# ESP32-H21 register map
Vendor: ESPRESSIF SYSTEMS (SHANGHAI) CO., LTD.; Series: ESP32 H-Series; File version: 1
CPU: RV32IMAC r0p0, little endian, no MPU, no FPU, 0 interrupt priority bits
Address unit: 32 bits
Registers are 32-bit, read-write, reset 0x0 unless marked. A register's access mark holds for its fields unless they carry their own. Offsets are from the block's base; [hi:lo] are bit positions; <NAME> marks a mode.

## PCR — PCR Peripheral
Base 0x60096000
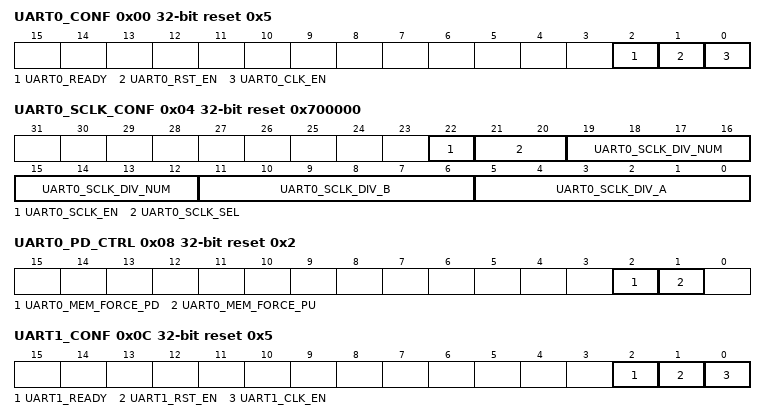
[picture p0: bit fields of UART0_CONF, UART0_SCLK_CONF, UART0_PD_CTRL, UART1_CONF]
0x00 UART0_CONF access per field reset 0x5 — UART0 configuration register
  [2] UART0_READY ro — Query this field after reset uart0 module
  [1] UART0_RST_EN rw — Set 0 to reset uart0 module
  [0] UART0_CLK_EN rw — Set 1 to enable uart0 apb clock
0x04 UART0_SCLK_CONF reset 0x700000 — UART0_SCLK configuration register
  [22] UART0_SCLK_EN — Set 1 to enable uart0 function clock
  [21:20] UART0_SCLK_SEL — set this field to select clock-source. 0: do not select anyone clock, 1: 80MHz, 2: FOSC, 3(default): XTAL.
  [19:12] UART0_SCLK_DIV_NUM — The integral part of the frequency divider factor of the uart0 function clock.
  [11:6] UART0_SCLK_DIV_B — The numerator of the frequency divider factor of the uart0 function clock.
  [5:0] UART0_SCLK_DIV_A — The denominator of the frequency divider factor of the uart0 function clock.
0x08 UART0_PD_CTRL reset 0x2 — UART0 power control register
  [2] UART0_MEM_FORCE_PD — Set this bit to force power up UART0 memory.
  [1] UART0_MEM_FORCE_PU — Set this bit to force power down UART0 memory.
0x0C UART1_CONF access per field reset 0x5 — UART1 configuration register
  [2] UART1_READY ro — Query this field after reset uart1 module
  [1] UART1_RST_EN rw — Set 0 to reset uart1 module
  [0] UART1_CLK_EN rw — Set 1 to enable uart1 apb clock
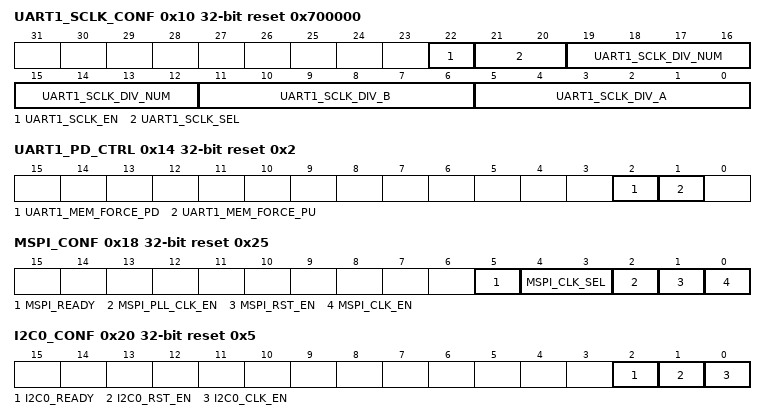
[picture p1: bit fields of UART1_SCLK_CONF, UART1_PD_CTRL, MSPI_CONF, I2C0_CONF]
0x10 UART1_SCLK_CONF reset 0x700000 — UART1_SCLK configuration register
  [22] UART1_SCLK_EN — Set 1 to enable uart0 function clock
  [21:20] UART1_SCLK_SEL — set this field to select clock-source. 0: do not select anyone clock, 1: 80MHz, 2: FOSC, 3(default): XTAL.
  [19:12] UART1_SCLK_DIV_NUM — The integral part of the frequency divider factor of the uart1 function clock.
  [11:6] UART1_SCLK_DIV_B — The numerator of the frequency divider factor of the uart1 function clock.
  [5:0] UART1_SCLK_DIV_A — The denominator of the frequency divider factor of the uart1 function clock.
0x14 UART1_PD_CTRL reset 0x2 — UART1 power control register
  [2] UART1_MEM_FORCE_PD — Set this bit to force power up UART1 memory.
  [1] UART1_MEM_FORCE_PU — Set this bit to force power down UART1 memory.
0x18 MSPI_CONF access per field reset 0x25 — MSPI configuration register
  [5] MSPI_READY ro — Query this field after reset mspi module
  [4:3] MSPI_CLK_SEL rw — set this field to select clock-source.
  [2] MSPI_PLL_CLK_EN rw — Set 1 to enable mspi pll clock
  [1] MSPI_RST_EN rw — Set 0 to reset mspi module
  [0] MSPI_CLK_EN rw — Set 1 to enable mspi clock, include mspi pll clock
0x1C MSPI_CLK_CONF — MSPI_CLK configuration register
  [7:0] MSPI_FAST_DIV_NUM — Set as one within (0,1,2) to generate div1(default)/div2/div4 of low-speed clock-source to drive clk_mspi_fast. Only avaiable whe the clck-source is a low-speed clock-source such as XTAL/FOSC.
0x20 I2C0_CONF access per field reset 0x5 — I2C configuration register
  [2] I2C0_READY ro — Query this field after reset i2c0 module
  [1] I2C0_RST_EN rw — Set 0 to reset i2c module
  [0] I2C0_CLK_EN rw — Set 1 to enable i2c apb clock
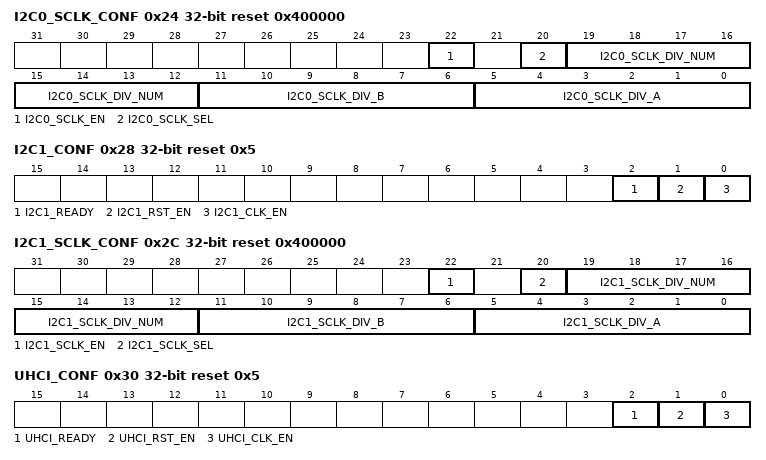
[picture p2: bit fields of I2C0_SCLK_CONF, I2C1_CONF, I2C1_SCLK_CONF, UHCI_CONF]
0x24 I2C0_SCLK_CONF reset 0x400000 — I2C_SCLK configuration register
  [22] I2C0_SCLK_EN — Set 1 to enable i2c function clock
  [20] I2C0_SCLK_SEL — set this field to select clock-source. 0(default): XTAL, 1: FOSC.
  [19:12] I2C0_SCLK_DIV_NUM — The integral part of the frequency divider factor of the i2c function clock.
  [11:6] I2C0_SCLK_DIV_B — The numerator of the frequency divider factor of the i2c function clock.
  [5:0] I2C0_SCLK_DIV_A — The denominator of the frequency divider factor of the i2c function clock.
0x28 I2C1_CONF access per field reset 0x5 — I2C configuration register
  [2] I2C1_READY ro — Query this field after reset i2c1 module
  [1] I2C1_RST_EN rw — Set 0 to reset i2c module
  [0] I2C1_CLK_EN rw — Set 1 to enable i2c apb clock
0x2C I2C1_SCLK_CONF reset 0x400000 — I2C_SCLK configuration register
  [22] I2C1_SCLK_EN — Set 1 to enable i2c function clock
  [20] I2C1_SCLK_SEL — set this field to select clock-source. 0(default): XTAL, 1: FOSC.
  [19:12] I2C1_SCLK_DIV_NUM — The integral part of the frequency divider factor of the i2c function clock.
  [11:6] I2C1_SCLK_DIV_B — The numerator of the frequency divider factor of the i2c function clock.
  [5:0] I2C1_SCLK_DIV_A — The denominator of the frequency divider factor of the i2c function clock.
0x30 UHCI_CONF access per field reset 0x5 — UHCI configuration register
  [2] UHCI_READY ro — Query this field after reset uhci module
  [1] UHCI_RST_EN rw — Set 0 to reset uhci module
  [0] UHCI_CLK_EN rw — Set 1 to enable uhci clock
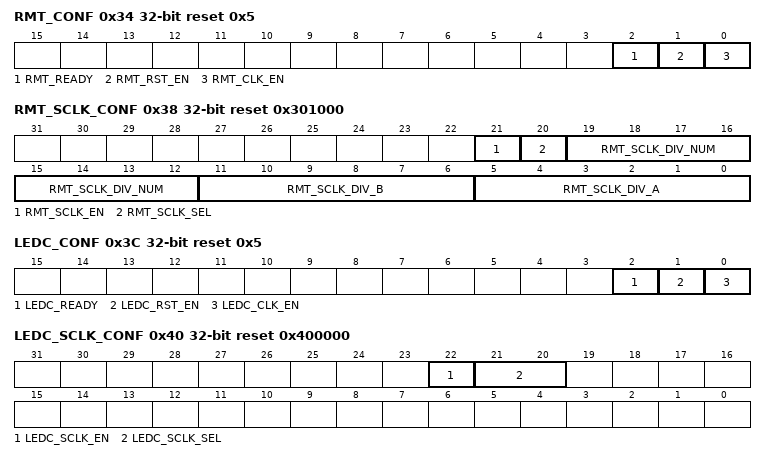
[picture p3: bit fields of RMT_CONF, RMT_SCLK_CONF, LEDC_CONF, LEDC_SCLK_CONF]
0x34 RMT_CONF access per field reset 0x5 — RMT configuration register
  [2] RMT_READY ro — Query this field after reset rmt module
  [1] RMT_RST_EN rw — Set 0 to reset rmt module
  [0] RMT_CLK_EN rw — Set 1 to enable rmt apb clock
0x38 RMT_SCLK_CONF reset 0x301000 — RMT_SCLK configuration register
  [21] RMT_SCLK_EN — Set 1 to enable rmt function clock
  [20] RMT_SCLK_SEL — set this field to select clock-source. 0: do not select anyone clock, 1(default): 80MHz, 2: FOSC, 3: XTAL.
  [19:12] RMT_SCLK_DIV_NUM — The integral part of the frequency divider factor of the rmt function clock.
  [11:6] RMT_SCLK_DIV_B — The numerator of the frequency divider factor of the rmt function clock.
  [5:0] RMT_SCLK_DIV_A — The denominator of the frequency divider factor of the rmt function clock.
0x3C LEDC_CONF access per field reset 0x5 — LEDC configuration register
  [2] LEDC_READY ro — Query this field after reset ledc module
  [1] LEDC_RST_EN rw — Set 0 to reset ledc module
  [0] LEDC_CLK_EN rw — Set 1 to enable ledc apb clock
0x40 LEDC_SCLK_CONF reset 0x400000 — LEDC_SCLK configuration register
  [22] LEDC_SCLK_EN — Set 1 to enable ledc function clock
  [21:20] LEDC_SCLK_SEL — set this field to select clock-source. 0(default): do not select anyone clock, 1: 80MHz, 2: FOSC, 3: XTAL.
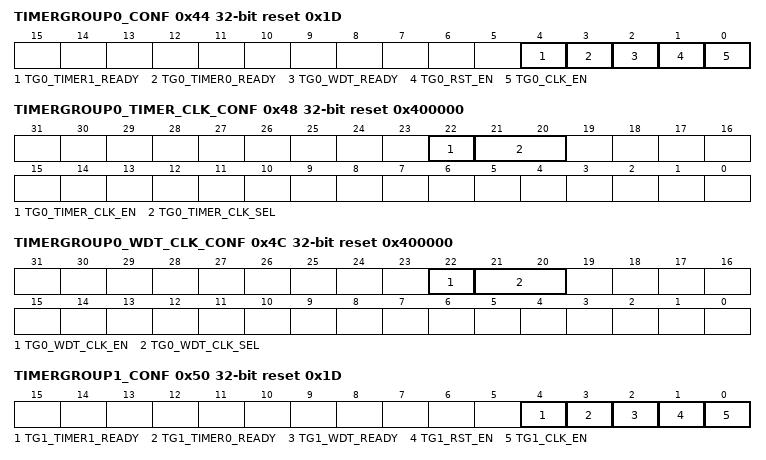
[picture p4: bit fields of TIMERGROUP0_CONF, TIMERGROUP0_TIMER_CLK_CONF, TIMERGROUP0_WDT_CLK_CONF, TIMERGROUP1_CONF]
0x44 TIMERGROUP0_CONF access per field reset 0x1D — TIMERGROUP0 configuration register
  [4] TG0_TIMER1_READY ro — reserved
  [3] TG0_TIMER0_READY ro — Query this field after reset timer_group0 timer0 module
  [2] TG0_WDT_READY ro — Query this field after reset timer_group0 wdt module
  [1] TG0_RST_EN rw — Set 0 to reset timer_group0 module
  [0] TG0_CLK_EN rw — Set 1 to enable timer_group0 apb clock
0x48 TIMERGROUP0_TIMER_CLK_CONF reset 0x400000 — TIMERGROUP0_TIMER_CLK configuration register
  [22] TG0_TIMER_CLK_EN — Set 1 to enable timer_group0 timer clock
  [21:20] TG0_TIMER_CLK_SEL — set this field to select clock-source. 0(default): XTAL, 1: 80MHz, 2: FOSC, 3: reserved.
0x4C TIMERGROUP0_WDT_CLK_CONF reset 0x400000 — TIMERGROUP0_WDT_CLK configuration register
  [22] TG0_WDT_CLK_EN — Set 1 to enable timer_group0 wdt clock
  [21:20] TG0_WDT_CLK_SEL — set this field to select clock-source. 0(default): XTAL, 1: 80MHz, 2: FOSC, 3: reserved.
0x50 TIMERGROUP1_CONF access per field reset 0x1D — TIMERGROUP1 configuration register
  [4] TG1_TIMER1_READY ro — reserved
  [3] TG1_TIMER0_READY ro — Query this field after reset timer_group1 timer0 module
  [2] TG1_WDT_READY ro — Query this field after reset timer_group1 wdt module
  [1] TG1_RST_EN rw — Set 0 to reset timer_group1 module
  [0] TG1_CLK_EN rw — Set 1 to enable timer_group1 apb clock
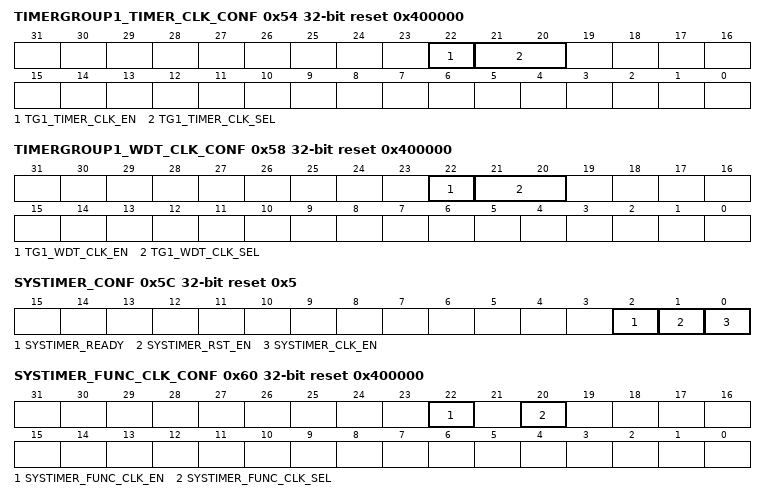
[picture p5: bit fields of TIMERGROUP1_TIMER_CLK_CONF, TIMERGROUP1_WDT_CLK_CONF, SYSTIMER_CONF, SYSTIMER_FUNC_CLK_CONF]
0x54 TIMERGROUP1_TIMER_CLK_CONF reset 0x400000 — TIMERGROUP1_TIMER_CLK configuration register
  [22] TG1_TIMER_CLK_EN — Set 1 to enable timer_group1 timer clock
  [21:20] TG1_TIMER_CLK_SEL — set this field to select clock-source. 0(default): XTAL, 1: 80MHz, 2: FOSC, 3: reserved.
0x58 TIMERGROUP1_WDT_CLK_CONF reset 0x400000 — TIMERGROUP1_WDT_CLK configuration register
  [22] TG1_WDT_CLK_EN — Set 1 to enable timer_group0 wdt clock
  [21:20] TG1_WDT_CLK_SEL — set this field to select clock-source. 0(default): XTAL, 1: 80MHz, 2: FOSC, 3: reserved.
0x5C SYSTIMER_CONF access per field reset 0x5 — SYSTIMER configuration register
  [2] SYSTIMER_READY ro — Query this field after reset systimer module
  [1] SYSTIMER_RST_EN rw — Set 0 to reset systimer module
  [0] SYSTIMER_CLK_EN rw — Set 1 to enable systimer apb clock
0x60 SYSTIMER_FUNC_CLK_CONF reset 0x400000 — SYSTIMER_FUNC_CLK configuration register
  [22] SYSTIMER_FUNC_CLK_EN — Set 1 to enable systimer function clock
  [20] SYSTIMER_FUNC_CLK_SEL — set this field to select clock-source. 0(default): XTAL, 1: FOSC.
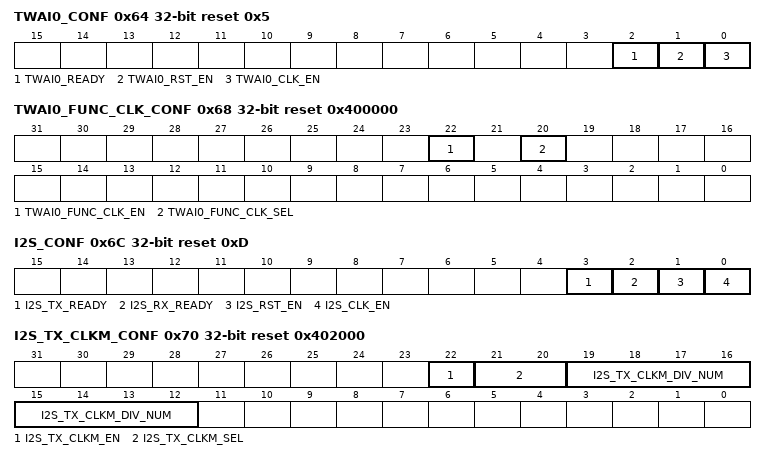
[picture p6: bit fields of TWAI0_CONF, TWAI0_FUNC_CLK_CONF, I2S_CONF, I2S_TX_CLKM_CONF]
0x64 TWAI0_CONF access per field reset 0x5 — TWAI0 configuration register
  [2] TWAI0_READY ro — Query this field after reset twai0 module
  [1] TWAI0_RST_EN rw — Set 0 to reset twai0 module
  [0] TWAI0_CLK_EN rw — Set 1 to enable twai0 apb clock
0x68 TWAI0_FUNC_CLK_CONF reset 0x400000 — TWAI0_FUNC_CLK configuration register
  [22] TWAI0_FUNC_CLK_EN — Set 1 to enable twai0 function clock
  [20] TWAI0_FUNC_CLK_SEL — set this field to select clock-source. 0(default): XTAL, 1: FOSC.
0x6C I2S_CONF access per field reset 0xD — I2S configuration register
  [3] I2S_TX_READY ro — Query this field before using i2s tx function, after reset i2s module
  [2] I2S_RX_READY ro — Query this field before using i2s rx function, after reset i2s module
  [1] I2S_RST_EN rw — Set 0 to reset i2s module
  [0] I2S_CLK_EN rw — Set 1 to enable i2s apb clock
0x70 I2S_TX_CLKM_CONF reset 0x402000 — I2S_TX_CLKM configuration register
  [22] I2S_TX_CLKM_EN — Set 1 to enable i2s_tx function clock
  [21:20] I2S_TX_CLKM_SEL — Select I2S Tx module source clock. 0: XTAL clock. 1: APLL. 2: CLK160. 3: I2S_MCLK_in.
  [19:12] I2S_TX_CLKM_DIV_NUM — Integral I2S TX clock divider value. f_I2S_CLK = f_I2S_CLK_S/(N+b/a). There will be (a-b) * n-div and b * (n+1)-div. So the average combination will be: for b <= a/2, z * [x * n-div + (n+1)-div] + y * n-div. For b > a/2, z * [n-div + x * (n+1)-div] + y * (n+1)-div.
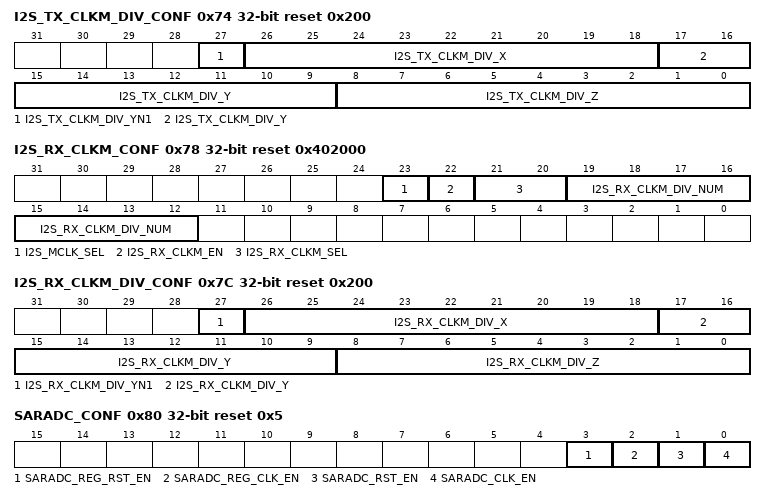
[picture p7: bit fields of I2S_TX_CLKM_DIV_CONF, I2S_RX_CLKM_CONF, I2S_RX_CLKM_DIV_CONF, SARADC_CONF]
0x74 I2S_TX_CLKM_DIV_CONF reset 0x200 — I2S_TX_CLKM_DIV configuration register
  [27] I2S_TX_CLKM_DIV_YN1 — For b <= a/2, the value of I2S_TX_CLKM_DIV_YN1 is 0 . For b > a/2, the value of I2S_TX_CLKM_DIV_YN1 is 1.
  [26:18] I2S_TX_CLKM_DIV_X — For b <= a/2, the value of I2S_TX_CLKM_DIV_X is (a/b) - 1. For b > a/2, the value of I2S_TX_CLKM_DIV_X is (a/(a-b)) - 1.
  [17:9] I2S_TX_CLKM_DIV_Y — For b <= a/2, the value of I2S_TX_CLKM_DIV_Y is (a%b) . For b > a/2, the value of I2S_TX_CLKM_DIV_Y is (a%(a-b)).
  [8:0] I2S_TX_CLKM_DIV_Z — For b <= a/2, the value of I2S_TX_CLKM_DIV_Z is b. For b > a/2, the value of I2S_TX_CLKM_DIV_Z is (a-b).
0x78 I2S_RX_CLKM_CONF reset 0x402000 — I2S_RX_CLKM configuration register
  [23] I2S_MCLK_SEL — This field is used to select master-clock. 0(default): clk_i2s_rx, 1: clk_i2s_tx
  [22] I2S_RX_CLKM_EN — Set 1 to enable i2s_rx function clock
  [21:20] I2S_RX_CLKM_SEL — Select I2S Rx module source clock. 0: no clock. 1: APLL. 2: CLK160. 3: I2S_MCLK_in.
  [19:12] I2S_RX_CLKM_DIV_NUM — Integral I2S clock divider value
0x7C I2S_RX_CLKM_DIV_CONF reset 0x200 — I2S_RX_CLKM_DIV configuration register
  [27] I2S_RX_CLKM_DIV_YN1 — For b <= a/2, the value of I2S_RX_CLKM_DIV_YN1 is 0 . For b > a/2, the value of I2S_RX_CLKM_DIV_YN1 is 1.
  [26:18] I2S_RX_CLKM_DIV_X — For b <= a/2, the value of I2S_RX_CLKM_DIV_X is (a/b) - 1. For b > a/2, the value of I2S_RX_CLKM_DIV_X is (a/(a-b)) - 1.
  [17:9] I2S_RX_CLKM_DIV_Y — For b <= a/2, the value of I2S_RX_CLKM_DIV_Y is (a%b) . For b > a/2, the value of I2S_RX_CLKM_DIV_Y is (a%(a-b)).
  [8:0] I2S_RX_CLKM_DIV_Z — For b <= a/2, the value of I2S_RX_CLKM_DIV_Z is b. For b > a/2, the value of I2S_RX_CLKM_DIV_Z is (a-b).
0x80 SARADC_CONF reset 0x5 — SARADC configuration register
  [3] SARADC_REG_RST_EN — Set 0 to reset apb_register of saradc module
  [2] SARADC_REG_CLK_EN — Set 1 to enable saradc apb clock
  [1] SARADC_RST_EN — Set 0 to reset function_register of saradc module
  [0] SARADC_CLK_EN — no use
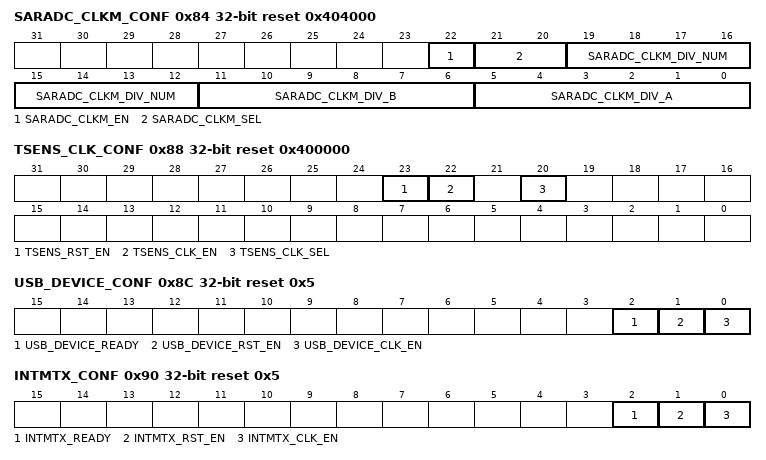
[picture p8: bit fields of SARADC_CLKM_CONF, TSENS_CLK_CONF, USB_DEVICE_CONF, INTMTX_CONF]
0x84 SARADC_CLKM_CONF reset 0x404000 — SARADC_CLKM configuration register
  [22] SARADC_CLKM_EN — Set 1 to enable saradc function clock
  [21:20] SARADC_CLKM_SEL — set this field to select clock-source. 0(default): XTAL, 1: 240MHz, 2: FOSC, 3: reserved.
  [19:12] SARADC_CLKM_DIV_NUM — The integral part of the frequency divider factor of the saradc function clock.
  [11:6] SARADC_CLKM_DIV_B — The numerator of the frequency divider factor of the saradc function clock.
  [5:0] SARADC_CLKM_DIV_A — The denominator of the frequency divider factor of the saradc function clock.
0x88 TSENS_CLK_CONF reset 0x400000 — TSENS_CLK configuration register
  [23] TSENS_RST_EN — Set 0 to reset tsens module
  [22] TSENS_CLK_EN — Set 1 to enable tsens clock
  [20] TSENS_CLK_SEL — set this field to select clock-source. 0(default): FOSC, 1: XTAL.
0x8C USB_DEVICE_CONF access per field reset 0x5 — USB_DEVICE configuration register
  [2] USB_DEVICE_READY ro — Query this field after reset usb_device module
  [1] USB_DEVICE_RST_EN rw — Set 0 to reset usb_device module
  [0] USB_DEVICE_CLK_EN rw — Set 1 to enable usb_device clock
0x90 INTMTX_CONF access per field reset 0x5 — INTMTX configuration register
  [2] INTMTX_READY ro — Query this field after reset intmtx module
  [1] INTMTX_RST_EN rw — Set 0 to reset intmtx module
  [0] INTMTX_CLK_EN rw — Set 1 to enable intmtx clock
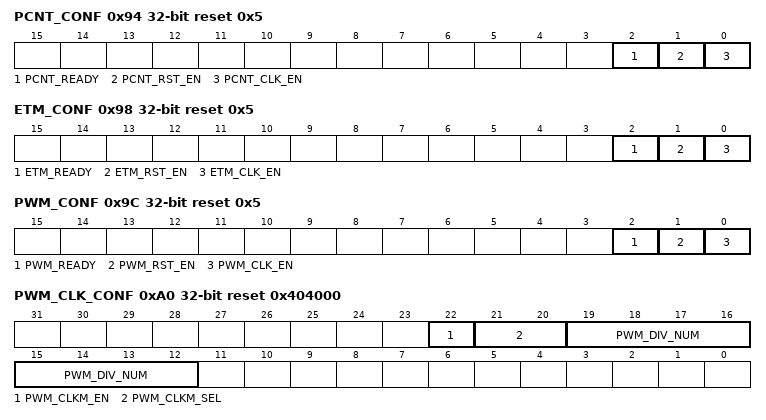
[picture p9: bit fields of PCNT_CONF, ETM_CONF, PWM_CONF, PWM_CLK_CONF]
0x94 PCNT_CONF access per field reset 0x5 — PCNT configuration register
  [2] PCNT_READY ro — Query this field after reset pcnt module
  [1] PCNT_RST_EN rw — Set 0 to reset pcnt module
  [0] PCNT_CLK_EN rw — Set 1 to enable pcnt clock
0x98 ETM_CONF access per field reset 0x5 — ETM configuration register
  [2] ETM_READY ro — Query this field after reset etm module
  [1] ETM_RST_EN rw — Set 0 to reset etm module
  [0] ETM_CLK_EN rw — Set 1 to enable etm clock
0x9C PWM_CONF access per field reset 0x5 — PWM configuration register
  [2] PWM_READY ro — Query this field after reset pwm module
  [1] PWM_RST_EN rw — Set 0 to reset pwm module
  [0] PWM_CLK_EN rw — Set 1 to enable pwm clock
0xA0 PWM_CLK_CONF reset 0x404000 — PWM_CLK configuration register
  [22] PWM_CLKM_EN — set this field as 1 to activate pwm clkm.
  [21:20] PWM_CLKM_SEL — set this field to select clock-source. 0(default): do not select anyone clock, 1: 160MHz, 2: XTAL, 3: FOSC.
  [19:12] PWM_DIV_NUM — The integral part of the frequency divider factor of the pwm function clock.
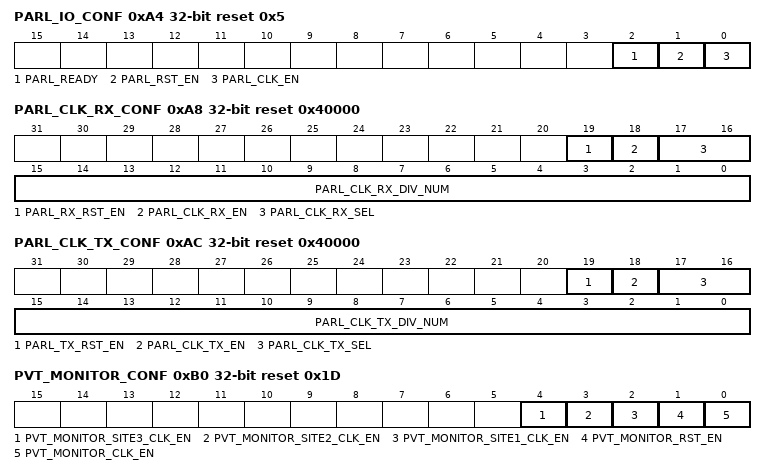
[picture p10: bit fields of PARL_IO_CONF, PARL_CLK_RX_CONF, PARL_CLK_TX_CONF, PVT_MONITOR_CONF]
0xA4 PARL_IO_CONF access per field reset 0x5 — PARL_IO configuration register
  [2] PARL_READY ro — Query this field after reset parl module
  [1] PARL_RST_EN rw — Set 0 to reset parl apb reg
  [0] PARL_CLK_EN rw — Set 1 to enable parl apb clock
0xA8 PARL_CLK_RX_CONF reset 0x40000 — PARL_CLK_RX configuration register
  [19] PARL_RX_RST_EN — Set 0 to reset parl rx module
  [18] PARL_CLK_RX_EN — Set 1 to enable parl rx clock
  [17:16] PARL_CLK_RX_SEL — set this field to select clock-source. 0(default): XTAL, 1: 240MHz, 2: FOSC, 3: user clock from pad.
  [15:0] PARL_CLK_RX_DIV_NUM — The integral part of the frequency divider factor of the parl rx clock.
0xAC PARL_CLK_TX_CONF reset 0x40000 — PARL_CLK_TX configuration register
  [19] PARL_TX_RST_EN — Set 0 to reset parl tx module
  [18] PARL_CLK_TX_EN — Set 1 to enable parl tx clock
  [17:16] PARL_CLK_TX_SEL — set this field to select clock-source. 0(default): XTAL, 1: 240MHz, 2: FOSC, 3: user clock from pad.
  [15:0] PARL_CLK_TX_DIV_NUM — The integral part of the frequency divider factor of the parl tx clock.
0xB0 PVT_MONITOR_CONF reset 0x1D — PVT_MONITOR configuration register
  [4] PVT_MONITOR_SITE3_CLK_EN — Set 1 to enable function clock of hp_peri pvt module
  [3] PVT_MONITOR_SITE2_CLK_EN — Set 1 to enable function clock of cpu pvt module
  [2] PVT_MONITOR_SITE1_CLK_EN — Set 1 to enable function clock of modem pvt module
  [1] PVT_MONITOR_RST_EN — Set 0 to reset all pvt monitor module
  [0] PVT_MONITOR_CLK_EN — Set 1 to enable apb clock of pvt module
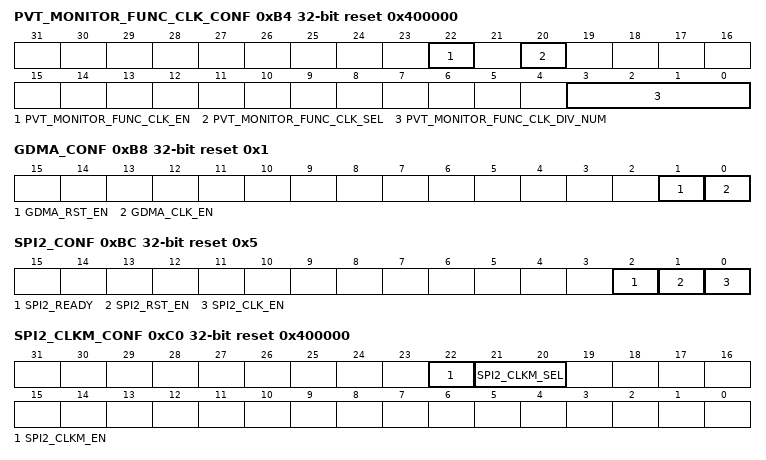
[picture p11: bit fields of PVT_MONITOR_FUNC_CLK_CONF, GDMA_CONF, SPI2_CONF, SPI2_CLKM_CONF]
0xB4 PVT_MONITOR_FUNC_CLK_CONF reset 0x400000 — PVT_MONITOR function clock configuration register
  [22] PVT_MONITOR_FUNC_CLK_EN — Set 1 to enable source clock of pvt sitex
  [20] PVT_MONITOR_FUNC_CLK_SEL — set this field to select clock-source. 0: XTAL, 1(default): 160MHz drived by SPLL divided by 3.
  [3:0] PVT_MONITOR_FUNC_CLK_DIV_NUM — The integral part of the frequency divider factor of the pvt_monitor function clock.
0xB8 GDMA_CONF reset 0x1 — GDMA configuration register
  [1] GDMA_RST_EN — Set 0 to reset gdma module
  [0] GDMA_CLK_EN — Set 1 to enable gdma clock
0xBC SPI2_CONF access per field reset 0x5 — SPI2 configuration register
  [2] SPI2_READY ro — Query this field after reset spi2 module
  [1] SPI2_RST_EN rw — Set 0 to reset spi2 module
  [0] SPI2_CLK_EN rw — Set 1 to enable spi2 apb clock
0xC0 SPI2_CLKM_CONF reset 0x400000 — SPI2_CLKM configuration register
  [22] SPI2_CLKM_EN — Set 1 to enable spi2 function clock
  [21:20] SPI2_CLKM_SEL — set this field to select clock-source. 0(default): XTAL, 1: 80MHz, 2: FOSC, 3: reserved.
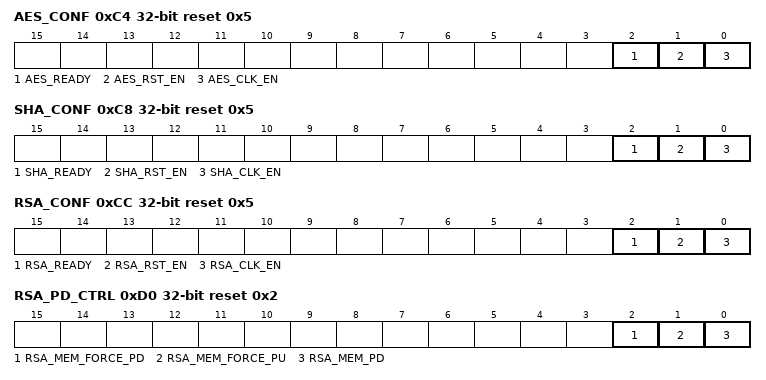
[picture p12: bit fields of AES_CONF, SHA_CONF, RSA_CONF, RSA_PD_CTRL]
0xC4 AES_CONF access per field reset 0x5 — AES configuration register
  [2] AES_READY ro — Query this field after reset aes module
  [1] AES_RST_EN rw — Set 0 to reset aes module
  [0] AES_CLK_EN rw — Set 1 to enable aes clock
0xC8 SHA_CONF access per field reset 0x5 — SHA configuration register
  [2] SHA_READY ro — Query this field after reset sha module
  [1] SHA_RST_EN rw — Set 0 to reset sha module
  [0] SHA_CLK_EN rw — Set 1 to enable sha clock
0xCC RSA_CONF access per field reset 0x5 — RSA configuration register
  [2] RSA_READY ro — Query this field after reset rsa module
  [1] RSA_RST_EN rw — Set 0 to reset rsa module
  [0] RSA_CLK_EN rw — Set 1 to enable rsa clock
0xD0 RSA_PD_CTRL reset 0x2 — RSA power control register
  [2] RSA_MEM_FORCE_PD — Set this bit to force power down rsa internal memory.
  [1] RSA_MEM_FORCE_PU — Set this bit to force power up rsa internal memory
  [0] RSA_MEM_PD — Set this bit to power down rsa internal memory.
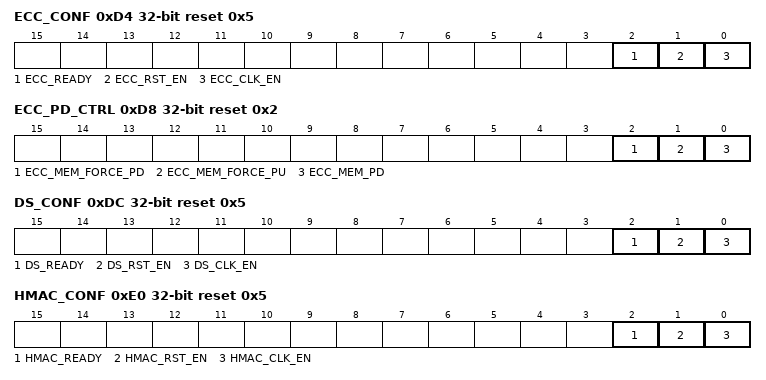
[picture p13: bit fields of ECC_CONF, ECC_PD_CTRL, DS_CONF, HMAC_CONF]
0xD4 ECC_CONF access per field reset 0x5 — ECC configuration register
  [2] ECC_READY ro — Query this field after reset ecc module
  [1] ECC_RST_EN rw — Set 0 to reset ecc module
  [0] ECC_CLK_EN rw — Set 1 to enable ecc clock
0xD8 ECC_PD_CTRL reset 0x2 — ECC power control register
  [2] ECC_MEM_FORCE_PD — Set this bit to force power down ecc internal memory.
  [1] ECC_MEM_FORCE_PU — Set this bit to force power up ecc internal memory
  [0] ECC_MEM_PD — Set this bit to power down ecc internal memory.
0xDC DS_CONF access per field reset 0x5 — DS configuration register
  [2] DS_READY ro — Query this field after reset ds module
  [1] DS_RST_EN rw — Set 0 to reset ds module
  [0] DS_CLK_EN rw — Set 1 to enable ds clock
0xE0 HMAC_CONF access per field reset 0x5 — HMAC configuration register
  [2] HMAC_READY ro — Query this field after reset hmac module
  [1] HMAC_RST_EN rw — Set 0 to reset hmac module
  [0] HMAC_CLK_EN rw — Set 1 to enable hmac clock
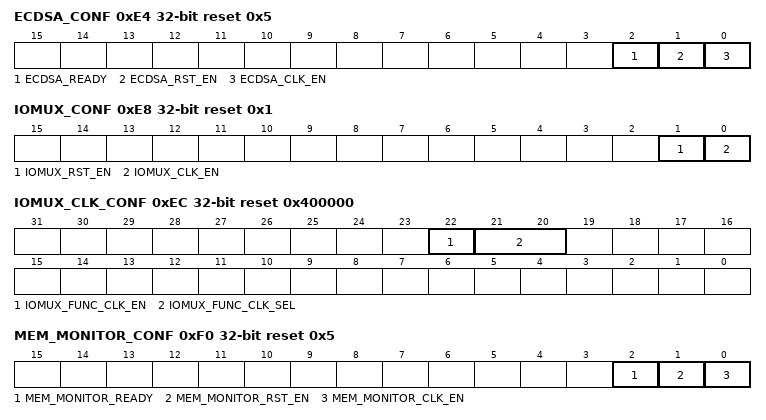
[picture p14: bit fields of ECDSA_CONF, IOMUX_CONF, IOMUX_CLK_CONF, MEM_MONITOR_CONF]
0xE4 ECDSA_CONF access per field reset 0x5 — ECDSA configuration register
  [2] ECDSA_READY ro — Query this field after reset ecdsa module
  [1] ECDSA_RST_EN rw — Set 0 to reset ecdsa module
  [0] ECDSA_CLK_EN rw — Set 1 to enable ecdsa clock
0xE8 IOMUX_CONF reset 0x1 — IOMUX configuration register
  [1] IOMUX_RST_EN — Set 0 to reset iomux module
  [0] IOMUX_CLK_EN — Set 1 to enable iomux apb clock
0xEC IOMUX_CLK_CONF reset 0x400000 — IOMUX_CLK configuration register
  [22] IOMUX_FUNC_CLK_EN — Set 1 to enable iomux function clock
  [21:20] IOMUX_FUNC_CLK_SEL — set this field to select clock-source. 0: do not select anyone clock, 1: 80MHz, 2: FOSC, 3(default): XTAL.
0xF0 MEM_MONITOR_CONF access per field reset 0x5 — MEM_MONITOR configuration register
  [2] MEM_MONITOR_READY ro — Query this field after reset mem_monitor module
  [1] MEM_MONITOR_RST_EN rw — Set 0 to reset mem_monitor module
  [0] MEM_MONITOR_CLK_EN rw — Set 1 to enable mem_monitor clock
0xF4 REGDMA_CONF — REGDMA configuration register
  [1] REGDMA_RST_EN — Set 0 to reset regdma module
  [0] REGDMA_CLK_EN — Set 1 to enable regdma clock
0xF8 TRACE_CONF reset 0x1 — TRACE configuration register
  [1] TRACE_RST_EN — Set 0 to reset trace module
  [0] TRACE_CLK_EN — Set 1 to enable trace clock
0xFC ASSIST_CONF reset 0x1 — ASSIST configuration register
  [1] ASSIST_RST_EN — Set 0 to reset assist module
  [0] ASSIST_CLK_EN — Set 1 to enable assist clock
0x100 CACHE_CONF reset 0x1 — CACHE configuration register
  [1] CACHE_RST_EN — Set 0 to reset cache module
  [0] CACHE_CLK_EN — Set 1 to enable cache clock
0x104 MODEM_CONF reset 0x2 — MODEM_APB configuration register
  [2] MODEM_RST_EN — Set this file as 1 to reset modem-subsystem.
  [1] MODEM_CLK_EN — xxxx
  [0] MODEM_CLK_SEL — xxxx
0x108 TIMEOUT_CONF — TIMEOUT configuration register
  [2] HP_TIMEOUT_RST_EN — Set 0 to reset hp_peri timeout module and hp_modem timeout module
  [1] CPU_TIMEOUT_RST_EN — Set 0 to reset cpu_peri timeout module
0x10C SYSCLK_CONF access per field reset 0x20000200 — SYSCLK configuration register
  [30:24] CLK_XTAL_FREQ ro — This field indicates the frequency(MHz) of XTAL.
  [17:16] SOC_CLK_SEL rw — This field is used to select clock source. 0: XTAL, 1: SPLL, 2: FOSC, 3: reserved.
  [15:8] HS_DIV_NUM ro — clk_hproot is div3 of SPLL if the clock-source is high-speed clock SPLL.
  [7:0] LS_DIV_NUM ro — clk_hproot is div1 of low-speed clock-source if clck-source is a low-speed clock-source such as XTAL/FOSC.
0x110 CPU_WAITI_CONF access per field reset 0xD — CPU_WAITI configuration register
  [7:4] CPU_WAITI_DELAY_NUM rw — This field used to set delay cycle when cpu enter waiti mode, after delay waiti_clk will close
  [3] CPU_WAIT_MODE_FORCE_ON rw — Set 1 to force cpu_waiti_clk enable.
  [2] PLL_FREQ_SEL ro — Reserved. This filed has been replaced by PCR_CPU_DIV_NUM
  [1:0] CPUPERIOD_SEL ro — Reserved. This filed has been replaced by PCR_CPU_DIV_NUM
0x114 CPU_FREQ_CONF — CPU_FREQ configuration register
  [7:0] CPU_DIV_NUM — Set this field to generate clk_cpu drived by clk_hproot. The clk_cpu is div1(default)/div2/div4 of clk_hproot. This field is only avaliable for low-speed clock-source such as XTAL/FOSC, and should be used together with PCR_AHB_DIV_NUM.
0x118 AHB_FREQ_CONF — AHB_FREQ configuration register
  [7:0] AHB_DIV_NUM — Set this field to generate clk_ahb drived by clk_hproot. The clk_ahb is div1(default)/div2/div4/div8 of clk_hproot. This field is only avaliable for low-speed clock-source such as XTAL/FOSC, and should be used together with PCR_CPU_DIV_NUM.
0x11C APB_FREQ_CONF — APB_FREQ configuration register
  [15:8] APB_DIV_NUM — Set as one within (0,1,3) to generate clk_apb drived by clk_ahb. The clk_apb is div1(default)/div2/div4 of clk_ahb.
  [7:0] APB_DECREASE_DIV_NUM — If this field's value is grater than PCR_APB_DIV_NUM, the clk_apb will be automatically down to clk_apb_decrease only when no access is on apb-bus, and will recover to the previous frequency when a new access appears on apb-bus. Set as one within (0,1,3) to set clk_apb_decrease as div1/div2/div4(default) of clk_ahb. Note that enable this function will reduce performance. Users can set this field as zero to disable the auto-decrease-apb-freq function. By default, this function is disable.
0x120 SYSCLK_FREQ_QUERY_0 ro reset 0x6008 — SYSCLK frequency query 0 register
  [17:8] PLL_FREQ — This field indicates the frequency(MHz) of SPLL.
  [7:0] FOSC_FREQ — This field indicates the frequency(MHz) of FOSC.
0x124 PLL_DIV_CLK_EN reset 0x3F — SPLL DIV clock-gating configuration register
  [5] PLL_40M_CLK_EN — This field is used to open 8 MHz clock (div12 of SPLL) drived from SPLL. 0: close, 1: open(default). Only avaliable when high-speed clock-source SPLL is active.
  [4] PLL_48M_CLK_EN — This field is used to open 16 MHz clock (div10 of SPLL) drived from SPLL. 0: close, 1: open(default). Only avaliable when high-speed clock-source SPLL is active.
  [3] PLL_80M_CLK_EN — This field is used to open 32 MHz clock (div6 of SPLL) drived from SPLL. 0: close, 1: open(default). Only avaliable when high-speed clock-source SPLL is active.
  [2] PLL_120M_CLK_EN — This field is used to open 48 MHz clock (div4 of SPLL) drived from SPLL. 0: close, 1: open(default). Only avaliable when high-speed clock-source SPLL is active.
  [1] PLL_160M_CLK_EN — This field is used to open 64 MHz clock (div3 of SPLL) drived from SPLL. 0: close, 1: open(default). Only avaliable when high-speed clock-source SPLL is active.
  [0] PLL_240M_CLK_EN — This field is used to open 96 MHz clock (SPLL) drived from SPLL. 0: close, 1: open(default). Only avaliable when high-speed clock-source SPLL is active.
0x128 CTRL_CLK_OUT_EN reset 0x7F — CLK_OUT_EN configuration register
  [6] CLK_XTAL_OEN — Set 1 to enable xtal clock
  [5] CLK_SDM_MOD_OEN — Reserved
  [4] CLK_DFM_INF_OEN — Reserved
  [3] CLK_ADC_INF_OEN — Reserved
  [2] CLK32_OEN — Set 1 to enable 32m clock
  [1] CLK16_OEN — Set 1 to enable 16m clock
  [0] CLK8_OEN — Set 1 to enable 8m clock
0x12C CTRL_TICK_CONF reset 0x10727 — TICK configuration register
  [17] RST_TICK_CNT — ******* Description ***********
  [16] TICK_ENABLE — ******* Description ***********
  [15:8] FOSC_TICK_NUM — ******* Description ***********
  [7:0] XTAL_TICK_NUM — ******* Description ***********
0x130 CTRL_32K_CONF reset 0x5 — 32KHz clock configuration register
  [3:2] _32K_MODEM_SEL — This field indicates which one 32KHz clock will be used by MODEM_SYSTEM. 1: XTAL32K(default), 2/3: 32KHz from pad GPIO0.
  [1:0] _32K_SEL — This field indicates which one 32KHz clock will be used by timergroup. 1: XTAL32K (default), 2/3: 32KHz from pad GPIO0.
0x134 SRAM_POWER_CONF_0 reset 0x6000 — HP SRAM/ROM configuration register
  [18:17] ROM_CLKGATE_FORCE_ON — 1: Force to open the clock and bypass the gate-clock when accessing the ROM. 0: A gate-clock will be used when accessing the ROM.
  [16:15] ROM_FORCE_PD — Set this bit to force power down ROM.
  [14:13] ROM_FORCE_PU — Set this bit to force power up ROM
0x138 SRAM_POWER_CONF_1 reset 0x1F — HP SRAM/ROM configuration register
  [29:25] SRAM_CLKGATE_FORCE_ON — 1: Force to open the clock and bypass the gate-clock when accessing the SRAM. 0: A gate-clock will be used when accessing the SRAM.
  [14:10] SRAM_FORCE_PD — Set this bit to force power down SRAM.
  [4:0] SRAM_FORCE_PU — Set this bit to force power up SRAM
0x13C SEC_CONF — xxxx
  [1:0] SEC_CLK_SEL
0x140 ADC_INV_PHASE_CONF — xxxx
  [0] CLK_ADC_INV_PHASE_ENA
0x144 SDM_INV_PHASE_CONF reset 0x400 — xxxx
  [11] CLK_TXLO_DIV2_EN — xxxx
  [10] CLK_SDM_EN — xxxx
  [9:6] CLK_SDM_TXLO_INV_PHASE_SEL — xxxx
  [5] CLK_TXLO_INV_PHASE_ENA — xxxx
  [4:1] CLK_SDM_INV_PHASE_SEL — xxxx
  [0] CLK_SDM_INV_PHASE_ENA — xxxx
0x148 BUS_CLK_UPDATE — xxxx
  [0] BUS_CLOCK_UPDATE
0x14C SAR_CLK_DIV reset 0x404 — xxxx
  [15:8] SAR1_CLK_DIV_NUM — xxxx
  [7:0] SAR2_CLK_DIV_NUM — xxxx
0x150 PWDET_SAR_CLK_CONF reset 0x107 — xxxx
  [8] PWDET_SAR_READER_EN — xxxx
  [7:0] PWDET_SAR_CLK_DIV_NUM — xxxx
0xFF0 RESET_EVENT_BYPASS reset 0x2 — reset event bypass backdoor configuration register
  [1] RESET_EVENT_BYPASS — This field is used to control reset event relationship for system-bus. 1: system bus (including arbiter/router) will only be reset by power-reset. some reset event will be bypass. 0: system bus (including arbiter/router) will not only be reset by power-reset, but also some reset event.
  [0] APM — This field is used to control reset event relationship for tee_reg/apm_reg/hp_system_reg. 1: tee_reg/apm_reg/hp_system_reg will only be reset by power-reset. some reset event will be bypass. 0: tee_reg/apm_reg/hp_system_reg will not only be reset by power-reset, but also some reset event.
0xFF4 FPGA_DEBUG reset 0xFFFFFFFF
  [31:0] FPGA_DEBUG — Only used in fpga debug.
0xFF8 CLOCK_GATE — PCR clock gating configure register
  [0] CLK_EN — Set this bit as 1 to force on clock gating.
0xFFC DATE reset 0x2409190
  [27:0] DATE — PCR version information.
